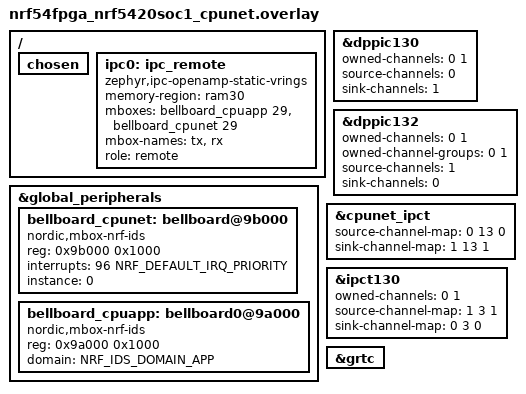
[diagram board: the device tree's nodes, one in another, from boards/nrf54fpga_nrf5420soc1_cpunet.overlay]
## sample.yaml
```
sample:
  description: Allows Zephyr to provide Bluetooth and IEEE 802.15.4 connectivity via
    RPMsg.
  name: Multiprotocol RPMsg
tests:
  sample.nrf5340.multiprotocol_rpmsg.build:
    build_only: true
    integration_platforms:
      - nrf5340dk_nrf5340_cpunet
    platform_allow: nrf5340dk_nrf5340_cpunet
    tags: ci_build
  sample.nrf54h20.multiprotocol_rpmsg.fpga:
    build_only: true
    integration_platforms:
      - nrf54h20dk_nrf54h20_cpurad@soc1
      - nrf54h20dk_nrf54h20_cpurad
    platform_allow: nrf54h20dk_nrf54h20_cpurad@soc1 nrf54h20dk_nrf54h20_cpurad
    tags: ci_build
    extra_configs:
      - CONFIG_EMULATOR_FPGA=y
  sample.nrf54h20.multiprotocol_rpmsg:
    build_only: true
    integration_platforms:
      - nrf54h20dk_nrf54h20_cpurad@soc1
    platform_allow: nrf54h20dk_nrf54h20_cpurad@soc1
    tags: ci_build
```

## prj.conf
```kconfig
## Disable serial and UART interface.
CONFIG_SERIAL=n
CONFIG_UART_CONSOLE=n

CONFIG_LOG=n

CONFIG_HEAP_MEM_POOL_SIZE=8192

CONFIG_MAIN_STACK_SIZE=2048
CONFIG_SYSTEM_WORKQUEUE_STACK_SIZE=2048
CONFIG_BT=y
CONFIG_BT_HCI_RAW=y
CONFIG_BT_MAX_CONN=16
CONFIG_BT_CTLR_ASSERT_HANDLER=y
CONFIG_BT_HCI_RAW_RESERVE=1

# Workaround: Unable to allocate command buffer when using K_NO_WAIT since
# Host number of completed commands does not follow normal flow control.
CONFIG_BT_BUF_CMD_TX_COUNT=10

CONFIG_ASSERT=y
CONFIG_DEBUG_INFO=y
CONFIG_EXCEPTION_STACK_TRACE=y

CONFIG_NRF_802154_SER_RADIO=y
CONFIG_NRF_RTC_TIMER_USER_CHAN_COUNT=3
CONFIG_IPC_SERVICE_BACKEND_RPMSG=y
```

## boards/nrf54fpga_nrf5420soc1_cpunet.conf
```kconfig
CONFIG_NRF_802154_ENCRYPTION=n
CONFIG_NRF_802154_TEMPERATURE_UPDATE=n

CONFIG_HEAP_MEM_POOL_SIZE=4096

CONFIG_NRF_GRTC_TIMER=n

CONFIG_MBOX=y
CONFIG_IPC_SERVICE=y
CONFIG_IPC_SERVICE_BACKEND_RPMSG=y
CONFIG_MBOX_NRFX_IDS=y

CONFIG_NRF_802154_ACK_TIMEOUT_CUSTOM_US=2000

# Due to bug in NRFX the assert must be temporarily disabled
CONFIG_ASSERT=n

CONFIG_NRF_REGTOOL_TOML_CONFIG_FILES="boards/nrf54fpga_nrf5420soc1_cpunet.toml"
```

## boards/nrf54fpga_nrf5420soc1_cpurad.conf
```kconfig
CONFIG_NRF_802154_ENCRYPTION=y
CONFIG_NRF_802154_TEMPERATURE_UPDATE=n

CONFIG_HEAP_MEM_POOL_SIZE=4096

CONFIG_NRF_GRTC_TIMER=n

CONFIG_MBOX=y
CONFIG_IPC_SERVICE=y
CONFIG_IPC_SERVICE_BACKEND_RPMSG=y
CONFIG_MBOX_NRFX_IDS=y

CONFIG_NRF_802154_ACK_TIMEOUT_CUSTOM_US=2000

# Due to bug in NRFX the assert must be temporarily disabled
CONFIG_ASSERT=n

CONFIG_NRF_REGTOOL_TOML_CONFIG_FILES="boards/nrf54fpga_nrf5420soc1_cpurad.toml"
```

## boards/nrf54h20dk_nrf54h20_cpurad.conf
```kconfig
CONFIG_NRF_802154_ENCRYPTION=y
CONFIG_NRF_802154_TEMPERATURE_UPDATE=n

CONFIG_HEAP_MEM_POOL_SIZE=4096

CONFIG_MBOX_NRFX_IDS=y

CONFIG_NRF_802154_ACK_TIMEOUT_CUSTOM_US=2000

# Due to bug in NRFX the assert must be temporarily disabled
CONFIG_ASSERT=n
```

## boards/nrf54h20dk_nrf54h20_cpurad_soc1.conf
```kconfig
CONFIG_NRF_802154_ENCRYPTION=y
CONFIG_NRF_802154_TEMPERATURE_UPDATE=n

CONFIG_HEAP_MEM_POOL_SIZE=4096

CONFIG_NRF_GRTC_TIMER=n

CONFIG_MBOX=y
CONFIG_IPC_SERVICE=y
CONFIG_IPC_SERVICE_BACKEND_RPMSG=y
CONFIG_MBOX_NRFX_IDS=y

CONFIG_NRF_802154_ACK_TIMEOUT_CUSTOM_US=2000

# Due to bug in NRFX the assert must be temporarily disabled
CONFIG_ASSERT=n

CONFIG_NRF_REGTOOL_TOML_CONFIG_FILES="boards/nrf54h20dk_nrf54h20_cpurad.toml"
```

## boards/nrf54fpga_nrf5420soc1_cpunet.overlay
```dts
/*
 * Copyright (c) 2021 Nordic Semiconductor ASA
 *
 * SPDX-License-Identifier: Apache-2.0
 */

#include <zephyr/dt-bindings/mbox/nrf-ids.h>

/ {
	chosen {
		/delete-property/ nordic,bellboard-cpuapp;
		/delete-property/ nordic,bellboard-cpunet;
	};

	ipc0: ipc_remote {
		compatible = "zephyr,ipc-openamp-static-vrings";
		memory-region = <&ram30>;
		mboxes = <&bellboard_cpuapp 29>,
			 <&bellboard_cpunet 29>;
		mbox-names = "tx", "rx";
		role = "remote";
		status = "okay";
	};
};

&global_peripherals {
	/*
	 * The default bellboard definitions use the IPC driver that is only compatible
	 * with the legacy IPC service. The bellboard definitions must be replaced with
	 * definitions compatible with the new MBOX driver used by the new IPC service
	 */
	/delete-node/ bellboard@9a000;
	/delete-node/ bellboard@9b000;

	bellboard_cpunet: bellboard@9b000 {
		compatible = "nordic,mbox-nrf-ids";
		reg = <0x9b000 0x1000>;
		interrupts = <96 NRF_DEFAULT_IRQ_PRIORITY>;
		instance = <0>;
		status = "okay";
		#mbox-cells = <1>;
	};

	bellboard_cpuapp: bellboard0@9a000 {
		compatible = "nordic,mbox-nrf-ids";
		reg = <0x9a000 0x1000>;
		domain = <NRF_IDS_DOMAIN_APP>;
		status = "okay";
		#mbox-cells = <1>;
	};
};

&dppic130 {
	owned-channels = <0 1>;
	source-channels = <0>;
	sink-channels = <1>;
	status = "okay";
};

&dppic132 {
	owned-channels = <0 1>;
	owned-channel-groups = <0 1>;
	source-channels = <1>;
	sink-channels = <0>;
	status = "okay";
};

&cpunet_ipct {
	source-channel-map = <0 13 0>;
	sink-channel-map = <1 13 1>;
};

&ipct130 {
	status = "okay";
	owned-channels = <0 1>;
	source-channel-map = <1 3 1>;
	sink-channel-map = <0 3 0>;
};

&grtc {
	status = "okay";
};
```

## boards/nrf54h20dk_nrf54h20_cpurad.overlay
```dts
/*
 * Copyright (c) 2021 Nordic Semiconductor ASA
 *
 * SPDX-License-Identifier: Apache-2.0
 */

&dppic130 {
	owned-channels = <0 1 2 3>;
	sink-channels = <0 1 2>;
	source-channels = <3>;
	nonsecure-channels = <0 1 2 3>;
	status = "okay";
};

&dppic132 {
	owned-channels = <0 1 2 3>;
	owned-channel-groups = <0 1>;
	source-channels = <0 1 2>;
	sink-channels = <3>;
	nonsecure-channels = <0 1 2 3>;
	status = "okay";
};

&cpurad_ipct {
	source-channel-links = <0 13 0>;
	sink-channel-links = <0 13 0
			      1 13 1
			      2 13 2>;
};

&ipct130 {
	status = "okay";
	owned-channels = <0 1 2>;
	source-channel-links = <0 3 0
				1 3 1
				2 3 2>;
	sink-channel-links = <0 3 0>;
};

&grtc {
	status = "okay";
};

ipc0: &ipc_cpuapp { };
```

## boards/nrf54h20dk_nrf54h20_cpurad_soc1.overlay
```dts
/*
 * Copyright (c) 2021 Nordic Semiconductor ASA
 *
 * SPDX-License-Identifier: Apache-2.0
 */

&dppic130 {
	owned-channels = <0 1>;
	source-channels = <0>;
	sink-channels = <1>;
	status = "okay";
};

&dppic132 {
	owned-channels = <0 1>;
	owned-channel-groups = <0 1>;
	source-channels = <1>;
	sink-channels = <0>;
	status = "okay";
};

&cpurad_ipct {
	source-channel-links = <0 13 0>;
	sink-channel-links = <1 13 1>;
};

&ipct130 {
	status = "okay";
	owned-channels = <0 1>;
	source-channel-links = <1 3 1>;
	sink-channel-links = <0 3 0>;
};

&grtc {
	status = "okay";
};

&systick {
	status = "okay";
};

// Currently there is no sufficient RAM capacity to hold the data for CPUSEC bellboard. Disable it.
&bellboard_cpusec {
	status = "disabled";
};

ipc0: &ipc_cpuapp { };
```

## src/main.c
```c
/*
 * Copyright (c) 2019-2021 Nordic Semiconductor ASA
 *
 * SPDX-License-Identifier: Apache-2.0
 */

#include <errno.h>
#include <stddef.h>
#include <stdio.h>
#include <string.h>

#include <zephyr/kernel.h>
#include <zephyr/arch/cpu.h>
#include <zephyr/sys/byteorder.h>
#include <zephyr/sys/util.h>
#include <zephyr/drivers/ipm.h>

#include <zephyr/ipc/ipc_service.h>

#include <zephyr/net/buf.h>
#include <zephyr/bluetooth/bluetooth.h>
#include <zephyr/bluetooth/l2cap.h>
#include <zephyr/bluetooth/hci.h>
#include <zephyr/bluetooth/buf.h>
#include <zephyr/bluetooth/hci_raw.h>

#include <nrf_802154_serialization_error.h>

#include "common/assert.h"

#include "zephyr/logging/log.h"
LOG_MODULE_REGISTER(multiprotocol_rpmsg);

static struct ipc_ept hci_ept;

static K_THREAD_STACK_DEFINE(tx_thread_stack, CONFIG_BT_HCI_TX_STACK_SIZE);
static struct k_thread tx_thread_data;
static K_FIFO_DEFINE(tx_queue);
static K_SEM_DEFINE(ipc_bound_sem, 0, 1);

#define HCI_RPMSG_CMD 0x01
#define HCI_RPMSG_ACL 0x02
#define HCI_RPMSG_SCO 0x03
#define HCI_RPMSG_EVT 0x04

static struct net_buf *hci_rpmsg_cmd_recv(uint8_t *data, size_t remaining)
{
	struct bt_hci_cmd_hdr *hdr = (void *)data;
	struct net_buf *buf;

	if (remaining < sizeof(*hdr)) {
		LOG_ERR("Not enought data for command header");
		return NULL;
	}

	buf = bt_buf_get_tx(BT_BUF_CMD, K_NO_WAIT, hdr, sizeof(*hdr));
	if (buf) {
		data += sizeof(*hdr);
		remaining -= sizeof(*hdr);
	} else {
		LOG_ERR("No available command buffers!");
		return NULL;
	}

	if (remaining != hdr->param_len) {
		LOG_ERR("Command payload length is not correct");
		net_buf_unref(buf);
		return NULL;
	}

	LOG_DBG("len %u", hdr->param_len);
	net_buf_add_mem(buf, data, remaining);

	return buf;
}

static struct net_buf *hci_rpmsg_acl_recv(uint8_t *data, size_t remaining)
{
	struct bt_hci_acl_hdr *hdr = (void *)data;
	struct net_buf *buf;

	if (remaining < sizeof(*hdr)) {
		LOG_ERR("Not enought data for ACL header");
		return NULL;
	}

	buf = bt_buf_get_tx(BT_BUF_ACL_OUT, K_NO_WAIT, hdr, sizeof(*hdr));
	if (buf) {
		data += sizeof(*hdr);
		remaining -= sizeof(*hdr);
	} else {
		LOG_ERR("No available ACL buffers!");
		return NULL;
	}

	if (remaining != sys_le16_to_cpu(hdr->len)) {
		LOG_ERR("ACL payload length is not correct");
		net_buf_unref(buf);
		return NULL;
	}

	LOG_DBG("len %u", remaining);
	net_buf_add_mem(buf, data, remaining);

	return buf;
}

static void hci_rpmsg_rx(uint8_t *data, size_t len)
{
	uint8_t pkt_indicator;
	struct net_buf *buf = NULL;
	size_t remaining = len;

	LOG_HEXDUMP_DBG(data, len, "RPMSG data:");

	pkt_indicator = *data++;
	remaining -= sizeof(pkt_indicator);

	switch (pkt_indicator) {
	case HCI_RPMSG_CMD:
		buf = hci_rpmsg_cmd_recv(data, remaining);
		break;

	case HCI_RPMSG_ACL:
		buf = hci_rpmsg_acl_recv(data, remaining);
		break;

	default:
		LOG_ERR("Unknown HCI type %u", pkt_indicator);
		return;
	}

	if (buf) {
		net_buf_put(&tx_queue, buf);

		LOG_HEXDUMP_DBG(buf->data, buf->len, "Final net buffer:");
	}
}

static void tx_thread(void *p1, void *p2, void *p3)
{
	while (1) {
		struct net_buf *buf;
		int err;

		/* Wait until a buffer is available */
		buf = net_buf_get(&tx_queue, K_FOREVER);
		/* Pass buffer to the stack */
		err = bt_send(buf);
		if (err) {
			LOG_ERR("Unable to send (err %d)", err);
			net_buf_unref(buf);
		}

		/* Give other threads a chance to run if tx_queue keeps getting
		 * new data all the time.
		 */
		k_yield();
	}
}

static int hci_rpmsg_send(struct net_buf *buf)
{
	uint8_t pkt_indicator;

	LOG_DBG("buf %p type %u len %u", (void *)buf, bt_buf_get_type(buf),
		buf->len);

	LOG_HEXDUMP_DBG(buf->data, buf->len, "Controller buffer:");

	switch (bt_buf_get_type(buf)) {
	case BT_BUF_ACL_IN:
		pkt_indicator = HCI_RPMSG_ACL;
		break;
	case BT_BUF_EVT:
		pkt_indicator = HCI_RPMSG_EVT;
		break;
	default:
		LOG_ERR("Unknown type %u", bt_buf_get_type(buf));
		net_buf_unref(buf);
		return -EINVAL;
	}
	net_buf_push_u8(buf, pkt_indicator);

	LOG_HEXDUMP_DBG(buf->data, buf->len, "Final HCI buffer:");
	ipc_service_send(&hci_ept, buf->data, buf->len);

	net_buf_unref(buf);

	return 0;
}

#if defined(CONFIG_BT_CTLR_ASSERT_HANDLER)
void bt_ctlr_assert_handle(char *file, uint32_t line)
{
	BT_ASSERT_MSG(false, "Controller assert in: %s at %d", file, line);
}
#endif /* CONFIG_BT_CTLR_ASSERT_HANDLER */

static void hci_ept_bound(void *priv)
{
	k_sem_give(&ipc_bound_sem);
}

static void hci_ept_recv(const void *data, size_t len, void *priv)
{
	LOG_INF("Received message of %u bytes.", len);
	hci_rpmsg_rx((uint8_t *) data, len);
}

static struct ipc_ept_cfg hci_ept_cfg = {
	.name = "nrf_bt_hci",
	.cb = {
		.bound    = hci_ept_bound,
		.received = hci_ept_recv,
	},
};

void main(void)
{
	int err;
	const struct device *hci_ipc_instance = DEVICE_DT_GET(DT_NODELABEL(ipc0));

	/* incoming events and data from the controller */
	static K_FIFO_DEFINE(rx_queue);

	LOG_DBG("Start");

	/* Enable the raw interface, this will in turn open the HCI driver */
	bt_enable_raw(&rx_queue);

	/* Spawn the TX thread and start feeding commands and data to the
	 * controller
	 */
	k_thread_create(&tx_thread_data, tx_thread_stack,
			K_THREAD_STACK_SIZEOF(tx_thread_stack), tx_thread,
			NULL, NULL, NULL, K_PRIO_COOP(7), 0, K_NO_WAIT);
	k_thread_name_set(&tx_thread_data, "HCI rpmsg TX");

	/* Initialize IPC service instance and register endpoint. */
	err = ipc_service_open_instance(hci_ipc_instance);
	if (err) {
		LOG_ERR("IPC service instance initialization failed: %d\n", err);
	}

	err = ipc_service_register_endpoint(hci_ipc_instance, &hci_ept, &hci_ept_cfg);
	if (err) {
		LOG_ERR("Registering endpoint failed with %d", err);
	}

	k_sem_take(&ipc_bound_sem, K_FOREVER);

	while (1) {
		struct net_buf *buf;

		buf = net_buf_get(&rx_queue, K_FOREVER);
		err = hci_rpmsg_send(buf);
		if (err) {
			LOG_ERR("Failed to send (err %d)", err);
		}
	}
}

void nrf_802154_serialization_error(const nrf_802154_ser_err_data_t *err)
{
	(void)err;
	__ASSERT(false, "802.15.4 serialization error");
}

void nrf_802154_sl_fault_handler(uint32_t id, int32_t line, const char *err)
{
	__ASSERT(false, "module_id: %u, line: %d, %s", id, line, err);
}

#if IS_ENABLED(CONFIG_SOC_PLATFORM_HALTIUM)

int check_status_flag(const struct device *arg)
{
	volatile uint8_t *p =
		(volatile uint8_t *) DT_REG_ADDR(DT_PHANDLE(DT_NODELABEL(ipc0), memory_region));

	/*
	 * Resetting the emulator doesn't also clear the memory. This means
	 * that from one run to another, the synchronization flag in the shared
	 * memory used by OpenAMP retains the old value. This causes the remote
	 * endpoint to wrongfully think that the host has already started
	 * causing mayhem and desperation for the poor dev soul trying to debug
	 * this. Reset the flag and make the remote core waiting until this is
	 * correctly set again before starting the sample.
	 *
	 * This workaround is necessary until SecDom resets the shared memory content
	 * to zero upon boot.
	 */

	while (*p != 0x0)
		;

	return 0;
}
SYS_INIT(check_status_flag, PRE_KERNEL_1, CONFIG_KERNEL_INIT_PRIORITY_DEFAULT);

#endif
```
